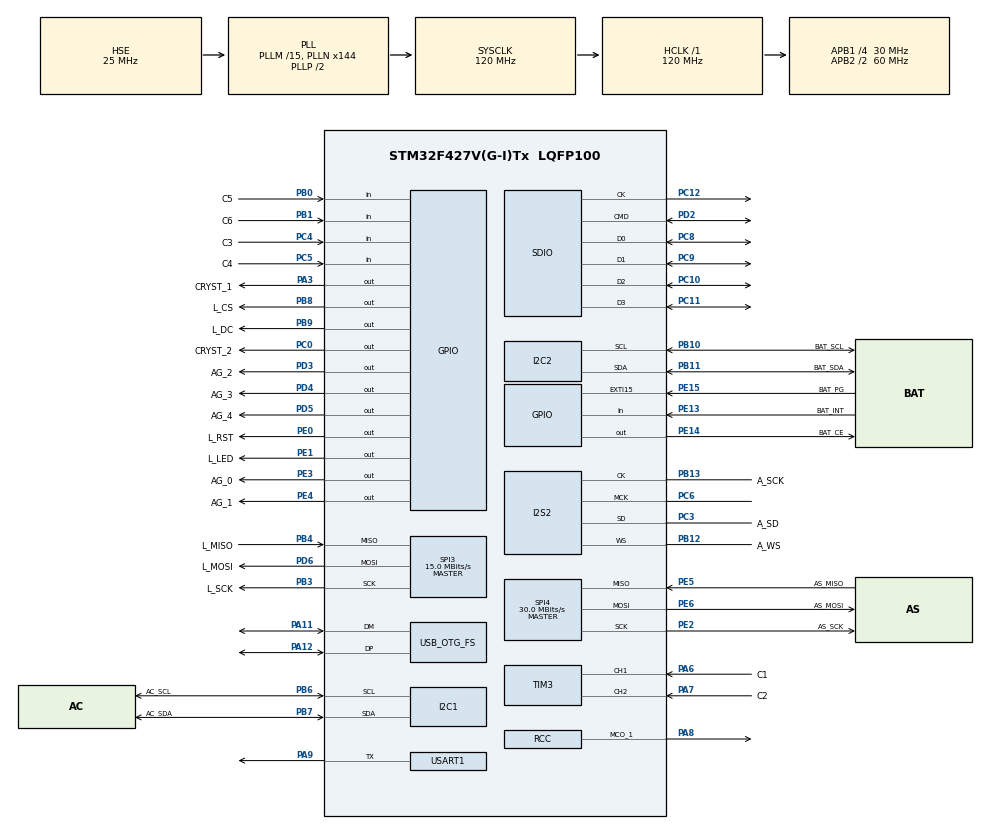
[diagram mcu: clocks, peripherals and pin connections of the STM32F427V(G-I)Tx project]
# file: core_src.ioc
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Dma.Request0=SPI3_TX
Dma.SPI3_TX.0.Direction=DMA_MEMORY_TO_PERIPH
Dma.SPI3_TX.0.FIFOMode=DMA_FIFOMODE_DISABLE
Dma.SPI3_TX.0.Instance=DMA1_Stream5
Dma.SPI3_TX.0.MemDataAlignment=DMA_MDATAALIGN_BYTE
Dma.SPI3_TX.0.MemInc=DMA_MINC_ENABLE
Dma.SPI3_TX.0.Mode=DMA_NORMAL
Dma.SPI3_TX.0.PeriphDataAlignment=DMA_PDATAALIGN_BYTE
Dma.SPI3_TX.0.PeriphInc=DMA_PINC_DISABLE
Dma.SPI3_TX.0.Priority=DMA_PRIORITY_HIGH
FATFS._CODE_PAGE=866
FATFS._FS_EXFAT=1
FATFS._FS_RPATH=2
FATFS._MAX_SS=4096
FATFS._USE_LFN=2
FREERTOS.Tasks01=defaultTask,0,1024,StartDefaultTask,Default,NULL,Dynamic,NULL,NULL
I2S2.AudioFreq=I2S_AUDIOFREQ_44K
I2S2.ErrorAudioFreq=10.97 %
I2S2.FullDuplexMode=I2S_FULLDUPLEXMODE_DISABLE
I2S2.Instance=SPI$Index
I2S2.RealAudioFreq=48.828 KHz
I2S2.VirtualMode=I2S_MODE_MASTER
Mcu.Family=STM32F4
Mcu.Name=STM32F427V(G-I)Tx
Mcu.Package=LQFP100
NVIC.DMA1_Stream5_IRQn=true\:5\:0\:false\:false\:true\:true\:false\:true
NVIC.OTG_FS_IRQn=true\:5\:0\:false\:false\:true\:true\:false\:true
NVIC.PriorityGroup=NVIC_PRIORITYGROUP_4
NVIC.SDIO_IRQn=true\:5\:0\:false\:false\:true\:true\:true\:true
NVIC.SPI3_IRQn=true\:5\:0\:false\:false\:true\:true\:true\:true
NVIC.SPI4_IRQn=true\:5\:0\:false\:false\:true\:true\:true\:true
NVIC.TIM8_TRG_COM_TIM14_IRQn=true\:0\:0\:false\:false\:true\:false\:false\:true
NVIC.TimeBase=TIM8_TRG_COM_TIM14_IRQn
NVIC.TimeBaseIP=TIM14
PA10.Signal=USB_OTG_FS_ID
PA11.Mode=Device_Only
PA11.Signal=USB_OTG_FS_DM
PA12.Mode=Device_Only
PA12.Signal=USB_OTG_FS_DP
PA13.Mode=Serial_Wire
PA13.Signal=SYS_JTMS-SWDIO
PA14.Mode=Serial_Wire
PA14.Signal=SYS_JTCK-SWCLK
PA3.GPIO_Label=CRYST_1
PA3.PinState=GPIO_PIN_SET
PA3.Signal=GPIO_Output
PA6.GPIO_Label=C1
PA6.Signal=S_TIM3_CH1
PA7.GPIO_Label=C2
PA7.Signal=S_TIM3_CH2
PA8.Mode=Clock-out-1
PA8.Signal=RCC_MCO_1
PA9.Mode=Half_duplex(single_wire_mode)
PA9.Signal=USART1_TX
PB0.GPIO_Label=C5
PB0.Signal=GPIO_Input
PB1.GPIO_Label=C6
PB1.Signal=GPIO_Input
PB10.GPIO_Label=BAT_SCL
PB10.Mode=I2C
PB10.Signal=I2C2_SCL
PB11.GPIO_Label=BAT_SDA
PB11.Mode=I2C
PB11.Signal=I2C2_SDA
PB12.GPIO_Label=A_WS
PB12.Mode=Half_Duplex_Master
PB12.Signal=I2S2_WS
PB13.GPIO_Label=A_SCK
PB13.Mode=Half_Duplex_Master
PB13.Signal=I2S2_CK
PB3.GPIO_Label=L_SCK
PB3.Mode=Full_Duplex_Master
PB3.Signal=SPI3_SCK
PB4.GPIO_Label=L_MISO
PB4.Mode=Full_Duplex_Master
PB4.Signal=SPI3_MISO
PB6.GPIO_Label=AC_SCL
PB6.Mode=I2C
PB6.Signal=I2C1_SCL
PB7.GPIO_Label=AC_SDA
PB7.Mode=I2C
PB7.Signal=I2C1_SDA
PB8.GPIO_Label=L_CS
PB8.Signal=GPIO_Output
PB9.GPIO_Label=L_DC
PB9.Signal=GPIO_Output
PC0.GPIO_Label=CRYST_2
PC0.Signal=GPIO_Output
PC10.Mode=SD_4_bits_Wide_bus
PC10.Signal=SDIO_D2
PC11.Mode=SD_4_bits_Wide_bus
PC11.Signal=SDIO_D3
PC12.GPIO_PuPd=GPIO_PULLUP
PC12.Mode=SD_4_bits_Wide_bus
PC12.Signal=SDIO_CK
PC3.GPIO_Label=A_SD
PC3.Mode=Half_Duplex_Master
PC3.Signal=I2S2_SD
PC4.GPIO_Label=C3
PC4.Signal=GPIO_Input
PC5.GPIO_Label=C4
PC5.Signal=GPIO_Input
PC6.Mode=Master_Clock_Activated
PC6.Signal=I2S2_MCK
PC8.GPIO_PuPd=GPIO_PULLUP
PC8.Mode=SD_4_bits_Wide_bus
PC8.Signal=SDIO_D0
PC9.Mode=SD_4_bits_Wide_bus
PC9.Signal=SDIO_D1
PD2.GPIO_PuPd=GPIO_PULLUP
PD2.Mode=SD_4_bits_Wide_bus
PD2.Signal=SDIO_CMD
PD3.GPIO_Label=AG_2
PD3.Signal=GPIO_Output
PD4.GPIO_Label=AG_3
PD4.Signal=GPIO_Output
PD5.GPIO_Label=AG_4
PD5.Signal=GPIO_Output
PD6.GPIO_Label=L_MOSI
PD6.Mode=Full_Duplex_Master
PD6.Signal=SPI3_MOSI
PE0.GPIO_Label=L_RST
PE0.Signal=GPIO_Output
PE1.GPIO_Label=L_LED
PE1.Signal=GPIO_Output
PE13.GPIO_Label=BAT_INT
PE13.Signal=GPIO_Input
PE14.GPIO_Label=BAT_CE
PE14.Signal=GPIO_Output
PE15.GPIO_Label=BAT_PG
PE15.Signal=GPXTI15
PE2.GPIO_Label=AS_SCK
PE2.Mode=Full_Duplex_Master
PE2.Signal=SPI4_SCK
PE3.GPIO_Label=AG_0
PE3.Signal=GPIO_Output
PE4.GPIO_Label=AG_1
PE4.Signal=GPIO_Output
PE5.GPIO_Label=AS_MISO
PE5.Mode=Full_Duplex_Master
PE5.Signal=SPI4_MISO
PE6.GPIO_Label=AS_MOSI
PE6.Mode=Full_Duplex_Master
PE6.Signal=SPI4_MOSI
PH0/OSC_IN.Mode=HSE-External-Clock-Source
PH0/OSC_IN.Signal=RCC_OSC_IN
PH1/OSC_OUT.Mode=HSE-External-Clock-Source
PH1/OSC_OUT.Signal=RCC_OSC_OUT
ProjectManager.HeapSize=0x2000
ProjectManager.StackSize=0x4000
ProjectManager.TargetToolchain=SW4STM32
RCC.48MHZClocksFreq_Value=48000000
RCC.AHBFreq_Value=120000000
RCC.APB1CLKDivider=RCC_HCLK_DIV4
RCC.APB1Freq_Value=30000000
RCC.APB1TimFreq_Value=60000000
RCC.APB2CLKDivider=RCC_HCLK_DIV2
RCC.APB2Freq_Value=60000000
RCC.APB2TimFreq_Value=120000000
RCC.CortexFreq_Value=120000000
RCC.HCLKFreq_Value=120000000
RCC.HSE_VALUE=25000000
RCC.HSI_VALUE=16000000
RCC.LSE_VALUE=32768
RCC.PLLI2SN=60
RCC.PLLM=15
RCC.PLLN=144
RCC.PLLQ=5
RCC.SYSCLKFreq_VALUE=120000000
RCC.SYSCLKSource=RCC_SYSCLKSOURCE_PLLCLK
RCC.VCOOutputFreq_Value=240000000
SDIO.ClockDiv=4
SH.S_TIM3_CH1.0=TIM3_CH1,Encoder_Interface
SH.S_TIM3_CH2.0=TIM3_CH2,Encoder_Interface
SPI3.BaudRatePrescaler=SPI_BAUDRATEPRESCALER_2
SPI3.CalculateBaudRate=15.0 MBits/s
SPI3.Direction=SPI_DIRECTION_2LINES
SPI3.Mode=SPI_MODE_MASTER
SPI3.VirtualType=VM_MASTER
SPI4.BaudRatePrescaler=SPI_BAUDRATEPRESCALER_2
SPI4.CalculateBaudRate=30.0 MBits/s
SPI4.Direction=SPI_DIRECTION_2LINES
SPI4.Mode=SPI_MODE_MASTER
SPI4.VirtualType=VM_MASTER
USART1.Mode=MODE_TX
USART1.VirtualMode=VM_ASYNC
USB_DEVICE.CLASS_NAME_FS=CDC
USB_DEVICE.VirtualMode-CDC_FS=Cdc
USB_DEVICE.VirtualModeFS=Cdc_FS
USB_OTG_FS.VirtualMode=Device_Only
VP_FATFS_VS_SDIO.Mode=SDIO
VP_FREERTOS_VS_CMSIS_V1.Mode=CMSIS_V1
VP_SYS_VS_tim14.Mode=TIM14
VP_USB_DEVICE_VS_USB_DEVICE_CDC_FS.Mode=CDC_FS
board=custom

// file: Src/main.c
/* USER CODE BEGIN Header */
/**
  ******************************************************************************
  * @file           : main.c
  * @brief          : Main program body
  ******************************************************************************
  * @attention
  *
  * <h2><center>&copy; Copyright (c) 2019 STMicroelectronics.
  * All rights reserved.</center></h2>
  *
  * This software component is licensed by ST under Ultimate Liberty license
  * SLA0044, the "License"; You may not use this file except in compliance with
  * the License. You may obtain a copy of the License at:
  *                             www.st.com/SLA0044
  *
  ******************************************************************************
  */
/* USER CODE END Header */

#include "main.h"
#include "cmsis_os.h"
#include "dma.h"
#include "fatfs.h"
#include "i2c.h"
#include "i2s.h"
#include "sdio.h"
#include "spi.h"
#include "tim.h"
#include "usart.h"
#include "usb_device.h"
#include "gpio.h"

/* USER CODE BEGIN Includes */
#include "gui.h"
/* USER CODE END Includes */

void SystemClock_Config(void);
void MX_FREERTOS_Init(void);

/* USER CODE BEGIN 0 */
int _write(int file, char *ptr, int len)
{
    HAL_UART_Transmit(&huart1, (uint8_t*)ptr, len, 10);
    return len;
}

/* USER CODE END 0 */

int main(void)
{
  /* USER CODE BEGIN 1 */
    MX_GPIO_Init();
    HAL_GPIO_WritePin(CRYST_1_GPIO_Port, CRYST_1_Pin, GPIO_PIN_SET);
  /* USER CODE END 1 */

  /* MCU Configuration--------------------------------------------------------*/

  /* Reset of all peripherals, Initializes the Flash interface and the Systick. */
  HAL_Init();

  /* Configure the system clock */
  SystemClock_Config();

  /* Initialize all configured peripherals */
  MX_GPIO_Init();
  MX_DMA_Init();
  MX_SPI3_Init();
  MX_SDIO_SD_Init();
  MX_I2S2_Init();
  MX_SPI4_Init();
  MX_I2C2_Init();
  MX_USART1_UART_Init();
  MX_I2C1_Init();
  MX_TIM3_Init();
  /* USER CODE BEGIN 2 */
  printf("Hello!\n");
  gui_init();
  /* USER CODE END 2 */

  /* Call init function for freertos objects (in freertos.c) */
  //MX_FREERTOS_Init();

  /* Start scheduler */
  //osKernelStart();

  /* We should never get here as control is now taken by the scheduler */

  /* Infinite loop */
  while (1)
  {

  }
}

void SystemClock_Config(void)
{
  RCC_OscInitTypeDef RCC_OscInitStruct = {0};
  RCC_ClkInitTypeDef RCC_ClkInitStruct = {0};
  RCC_PeriphCLKInitTypeDef PeriphClkInitStruct = {0};

  /** Configure the main internal regulator output voltage
  */
  __HAL_RCC_PWR_CLK_ENABLE();
  __HAL_PWR_VOLTAGESCALING_CONFIG(PWR_REGULATOR_VOLTAGE_SCALE3);
  /** Initializes the CPU, AHB and APB busses clocks
  */
  RCC_OscInitStruct.OscillatorType = RCC_OSCILLATORTYPE_HSI|RCC_OSCILLATORTYPE_HSE;
  RCC_OscInitStruct.HSEState = RCC_HSE_BYPASS;
  RCC_OscInitStruct.HSIState = RCC_HSI_ON;
  RCC_OscInitStruct.HSICalibrationValue = RCC_HSICALIBRATION_DEFAULT;
  RCC_OscInitStruct.PLL.PLLState = RCC_PLL_ON;
  RCC_OscInitStruct.PLL.PLLSource = RCC_PLLSOURCE_HSE;
  RCC_OscInitStruct.PLL.PLLM = 15;
  RCC_OscInitStruct.PLL.PLLN = 144;
  RCC_OscInitStruct.PLL.PLLP = RCC_PLLP_DIV2;
  RCC_OscInitStruct.PLL.PLLQ = 5;
  if (HAL_RCC_OscConfig(&RCC_OscInitStruct) != HAL_OK)
  {
    Error_Handler();
  }
  /** Initializes the CPU, AHB and APB busses clocks
  */
  RCC_ClkInitStruct.ClockType = RCC_CLOCKTYPE_HCLK|RCC_CLOCKTYPE_SYSCLK
                              |RCC_CLOCKTYPE_PCLK1|RCC_CLOCKTYPE_PCLK2;
  RCC_ClkInitStruct.SYSCLKSource = RCC_SYSCLKSOURCE_PLLCLK;
  RCC_ClkInitStruct.AHBCLKDivider = RCC_SYSCLK_DIV1;
  RCC_ClkInitStruct.APB1CLKDivider = RCC_HCLK_DIV4;
  RCC_ClkInitStruct.APB2CLKDivider = RCC_HCLK_DIV2;

  if (HAL_RCC_ClockConfig(&RCC_ClkInitStruct, FLASH_LATENCY_3) != HAL_OK)
  {
    Error_Handler();
  }
  PeriphClkInitStruct.PeriphClockSelection = RCC_PERIPHCLK_I2S;
  PeriphClkInitStruct.PLLI2S.PLLI2SN = 60;
  PeriphClkInitStruct.PLLI2S.PLLI2SR = 2;
  if (HAL_RCCEx_PeriphCLKConfig(&PeriphClkInitStruct) != HAL_OK)
  {
    Error_Handler();
  }
  HAL_RCC_MCOConfig(RCC_MCO1, RCC_MCO1SOURCE_HSI, RCC_MCODIV_1);
}

void HAL_TIM_PeriodElapsedCallback(TIM_HandleTypeDef *htim)
{
  if (htim->Instance == TIM14) {
    HAL_IncTick();
  }
}

void Error_Handler(void)
{
  /* USER CODE BEGIN Error_Handler_Debug */
  /* User can add his own implementation to report the HAL error return state */
    printf("Error!\n");
  /* USER CODE END Error_Handler_Debug */
}

/************************ (C) COPYRIGHT STMicroelectronics *****END OF FILE****/
